VERSION "HIPBNYYYYYYYYYYYYYYYYYYYYYYYYYYYNNNYNNNNNN/4/%%%/4/'%**4NNN///"

NS_ :

BS_:

BU_: P4USimulation

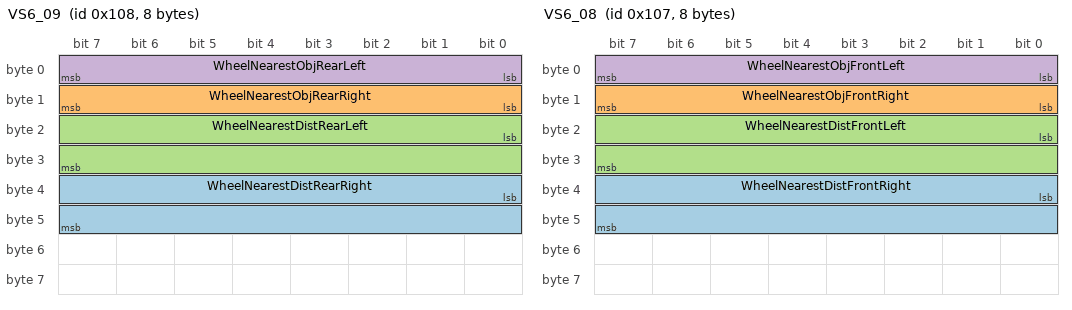
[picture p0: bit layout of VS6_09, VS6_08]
BO_ 264 VS6_09: 8 Vector__XXX
 SG_ WheelNearestDistRearRight : 32|16@1+ (1,0) [0|65535] "mm" Vector__XXX
 SG_ WheelNearestObjRearRight : 8|8@1+ (1,0) [0|255] "ID" Vector__XXX
 SG_ WheelNearestDistRearLeft : 16|16@1+ (1,0) [0|65535] "mm" Vector__XXX
 SG_ WheelNearestObjRearLeft : 0|8@1+ (1,0) [0|255] "ID" Vector__XXX

BO_ 263 VS6_08: 8 Vector__XXX
 SG_ WheelNearestDistFrontRight : 32|16@1+ (1,0) [0|65535] "mm" Vector__XXX
 SG_ WheelNearestObjFrontRight : 8|8@1+ (1,0) [0|255] "ID" Vector__XXX
 SG_ WheelNearestDistFrontLeft : 16|16@1+ (1,0) [0|65535] "mm" Vector__XXX
 SG_ WheelNearestObjFrontLeft : 0|8@1+ (1,0) [0|255] "ID" Vector__XXX

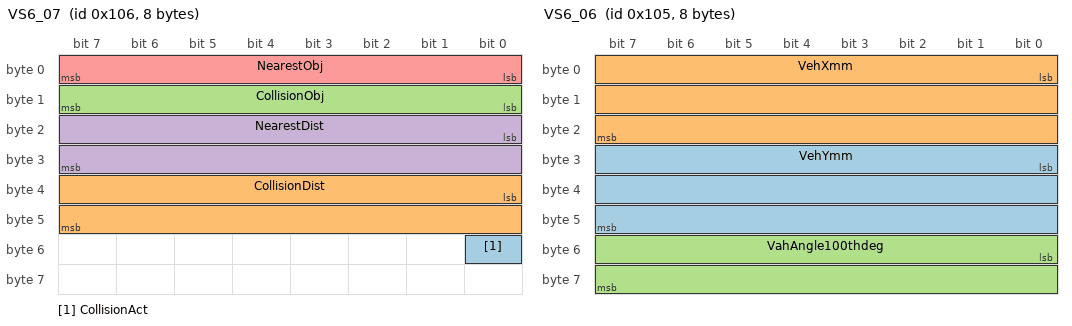
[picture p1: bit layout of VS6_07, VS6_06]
BO_ 262 VS6_07: 8 Vector__XXX
 SG_ CollisionAct : 48|1@1+ (1,0) [0|0] "" Vector__XXX
 SG_ CollisionDist : 32|16@1+ (1,0) [0|65535] "mm" Vector__XXX
 SG_ CollisionObj : 8|8@1+ (1,0) [0|255] "ID" Vector__XXX
 SG_ NearestDist : 16|16@1+ (1,0) [0|65535] "mm" Vector__XXX
 SG_ NearestObj : 0|8@1+ (1,0) [0|255] "ID" Vector__XXX

BO_ 261 VS6_06: 8 Vector__XXX
 SG_ VehYmm : 24|24@1- (1,0) [-8388608|8388607] "mm" Vector__XXX
 SG_ VehXmm : 0|24@1- (1,0) [-8388608|8388607] "mm" Vector__XXX
 SG_ VahAngle100thdeg : 48|16@1- (1,0) [0|0] "100thdeg" Vector__XXX

BO_ 260 VS6_05: 8 Vector__XXX
 SG_ WheelAngleFront : 0|16@1- (0.01,0) [-327.68|327.67] "degree" Vector__XXX
 SG_ WheelAngleRear : 16|16@1- (0.01,0) [-327.68|327.67] "degree" Vector__XXX

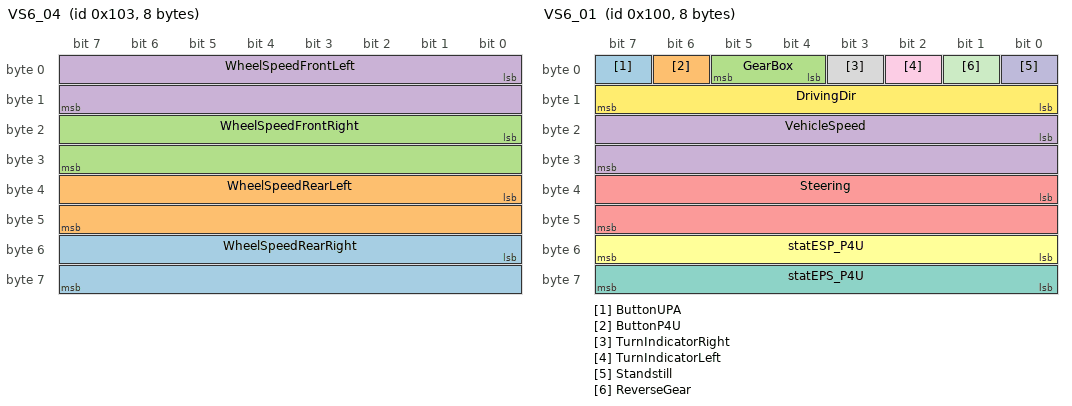
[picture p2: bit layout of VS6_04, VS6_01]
BO_ 259 VS6_04: 8 Vector__XXX
 SG_ WheelSpeedRearRight : 48|16@1- (0.01,0) [-327.68|327.67] "km/h" Vector__XXX
 SG_ WheelSpeedRearLeft : 32|16@1- (0.01,0) [-327.68|327.67] "km/h" Vector__XXX
 SG_ WheelSpeedFrontRight : 16|16@1- (0.01,0) [-327.68|327.67] "km/h" Vector__XXX
 SG_ WheelSpeedFrontLeft : 0|16@1- (0.01,0) [-327.68|327.67] "km/h" Vector__XXX

BO_ 256 VS6_01: 8 Vector__XXX
 SG_ ButtonUPA : 7|1@1+ (1,0) [0|0] "" Vector__XXX
 SG_ ButtonP4U : 6|1@1+ (1,0) [0|0] "" Vector__XXX
 SG_ GearBox : 4|2@1+ (1,0) [0|3] "" Vector__XXX
 SG_ VehicleSpeed : 16|16@1+ (0.01,0) [0|655.35] "km/h"  P4USimulation
 SG_ Steering : 32|16@1- (1,0) [-32768|32767] "see_ratio_table"  P4USimulation
 SG_ statESP_P4U : 48|8@1+ (1,0) [0|255] ""  P4USimulation
 SG_ statEPS_P4U : 56|8@1+ (1,0) [0|255] ""  P4USimulation
 SG_ TurnIndicatorRight : 3|1@1+ (1,0) [0|1] ""  P4USimulation
 SG_ TurnIndicatorLeft : 2|1@1+ (1,0) [0|1] ""  P4USimulation
 SG_ Standstill : 0|1@1+ (1,0) [0|1] ""  P4USimulation
 SG_ ReverseGear : 1|1@1+ (1,0) [0|1] ""  P4USimulation
 SG_ DrivingDir : 8|8@1- (1,0) [-128|127] ""  P4USimulation

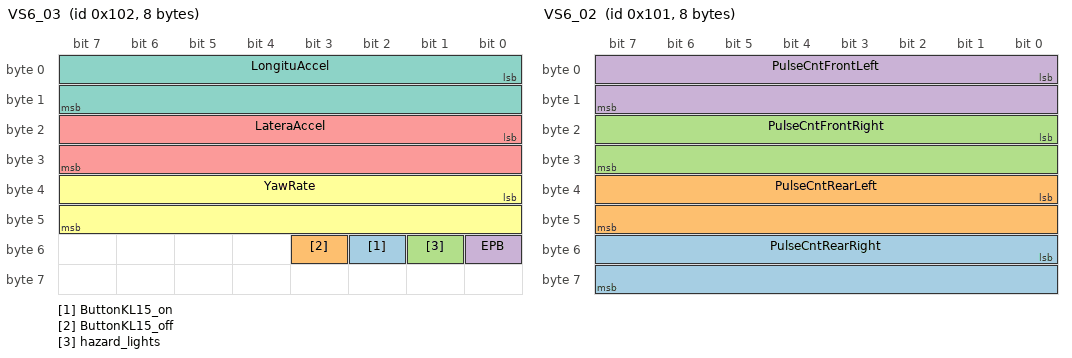
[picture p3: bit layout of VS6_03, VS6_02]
BO_ 258 VS6_03: 8 Vector__XXX
 SG_ ButtonKL15_on : 50|1@1+ (1,0) [0|0] "" Vector__XXX
 SG_ ButtonKL15_off : 51|1@1+ (1,0) [0|0] "" Vector__XXX
 SG_ hazard_lights : 49|1@1+ (1,0) [0|0] "-" Vector__XXX
 SG_ EPB : 48|1@1- (1,0) [0|0] "-" Vector__XXX
 SG_ LateraAccel : 16|16@1- (0.01,0) [0|0] "m/sec^2"  P4USimulation
 SG_ YawRate : 32|16@1- (0.01,0) [-327.68|327.67] "degree/sec"  P4USimulation
 SG_ LongituAccel : 0|16@1- (0.01,0) [0|0] "m/sec^2"  P4USimulation

BO_ 257 VS6_02: 8 Vector__XXX
 SG_ PulseCntRearRight : 48|16@1+ (1,0) [0|65535] ""  P4USimulation
 SG_ PulseCntRearLeft : 32|16@1+ (1,0) [0|65535] ""  P4USimulation
 SG_ PulseCntFrontRight : 16|16@1+ (1,0) [0|65535] ""  P4USimulation
 SG_ PulseCntFrontLeft : 0|16@1+ (1,0) [0|65535] ""  P4USimulation

EV_ EnvMultiMsg_VS6: 0 [0|0] "" 0 1 DUMMY_NODE_VECTOR0 Vector__XXX;

EV_ EnvSendVS6_Standstill: 0 [0|1] "" 0 2 DUMMY_NODE_VECTOR0 Vector__XXX;

EV_ EnvSendVS6_statESP_P4U: 0 [0|1] "" 0 3 DUMMY_NODE_VECTOR0 Vector__XXX;

EV_ EnvSendVS6_statEPS_P4U: 0 [0|1] "" 0 4 DUMMY_NODE_VECTOR0 Vector__XXX;

EV_ EnvSendVS6_LongituAccel: 0 [0|1] "" 0 5 DUMMY_NODE_VECTOR0 Vector__XXX;

EV_ EnvSendVS6_LateraAccel: 0 [0|1] "" 0 6 DUMMY_NODE_VECTOR0 Vector__XXX;

EV_ EnvSendVS6_DrivingDir: 0 [0|1] "" 0 7 DUMMY_NODE_VECTOR0 Vector__XXX;

EV_ EnvSendVS6_ReverseGear: 0 [0|1] "" 0 8 DUMMY_NODE_VECTOR0 Vector__XXX;

EV_ EnvSendVS6_SteeringWheelAngle: 0 [0|1] "" 0 9 DUMMY_NODE_VECTOR0 Vector__XXX;

EV_ EnvSendVS6_YawRate: 0 [0|1] "" 0 10 DUMMY_NODE_VECTOR0 Vector__XXX;

EV_ EnvSendVS6_VehicleSpeed: 0 [0|1] "" 0 11 DUMMY_NODE_VECTOR0 Vector__XXX;

EV_ EnvSendVS6_TurnIndicatorRight: 0 [0|1] "" 0 12 DUMMY_NODE_VECTOR0 Vector__XXX;

EV_ EnvSendVS6_TurnIndicatorLeft: 0 [0|1] "" 0 13 DUMMY_NODE_VECTOR0 Vector__XXX;

EV_ EnvSendVS6_PulseCntFrontRight: 0 [0|1] "" 0 14 DUMMY_NODE_VECTOR0 Vector__XXX;

EV_ EnvSendVS6_PulseCntFrontLeft: 0 [0|1] "" 0 15 DUMMY_NODE_VECTOR0 Vector__XXX;

EV_ EnvSendVS6_PulseCntRearLeft: 0 [0|1] "" 0 16 DUMMY_NODE_VECTOR0 Vector__XXX;

EV_ EnvSendVS6_PulseCntRearRight: 0 [0|1] "" 0 17 DUMMY_NODE_VECTOR0 Vector__XXX;

CM_ "CAN communication matrix for body electronics
*******************************************************

implemented: turn lights, warning lights, windows


";
CM_ SG_ 264 WheelNearestDistRearRight "Direct distance from wheel to nearest object in mm";
CM_ SG_ 264 WheelNearestObjRearRight "Id of nearest object from wheel";
CM_ SG_ 264 WheelNearestDistRearLeft "Direct distance from wheel to nearest object in mm";
CM_ SG_ 264 WheelNearestObjRearLeft "Id of nearest object from wheel";
CM_ SG_ 263 WheelNearestDistFrontRight "Direct distance from wheel to nearest object in mm";
CM_ SG_ 263 WheelNearestObjFrontRight "Id of nearest object from wheel";
CM_ SG_ 263 WheelNearestDistFrontLeft "Direct distance from wheel to nearest object in mm";
CM_ SG_ 263 WheelNearestObjFrontLeft "Id of nearest object from wheel";
CM_ SG_ 262 CollisionAct "Collision active with an obstacle";
CM_ SG_ 262 CollisionDist "Distance to nearest object in driving tube in mm (0=collision active)";
CM_ SG_ 262 CollisionObj "Id of nearest object in driving tube";
CM_ SG_ 262 NearestDist "Direct distance from vehicle to nearest object in mm";
CM_ SG_ 262 NearestObj "Id of nearest object to vehicle";
CM_ SG_ 260 WheelAngleFront "Wheel Angle of front axis.";
CM_ SG_ 260 WheelAngleRear "Wheel Angle of rear axis for simulation of a vehicle with steerable rear axis.";
CM_ SG_ 256 VehicleSpeed "Vehicle speed";
CM_ SG_ 256 Steering "Steering angle";
CM_ SG_ 256 statESP_P4U "Status ESP to Park4U";
CM_ SG_ 256 statEPS_P4U "Status EPS to Park4U";
CM_ SG_ 256 TurnIndicatorRight "Turn indicator right";
CM_ SG_ 256 TurnIndicatorLeft "Turn indicator left";
CM_ SG_ 256 Standstill "Standstill";
CM_ SG_ 256 ReverseGear "Reverse gear";
CM_ SG_ 256 DrivingDir "Driving direction";
CM_ SG_ 258 LateraAccel "Lateral acceleration sensor";
CM_ SG_ 258 YawRate "Yaw rate sensor";
CM_ SG_ 258 LongituAccel "Longitudinal acceleration sensor";
CM_ SG_ 257 PulseCntRearRight "Pulse counter rear right";
CM_ SG_ 257 PulseCntRearLeft "Pulse counter rear left";
CM_ SG_ 257 PulseCntFrontRight "Pulse counter front right";
CM_ SG_ 257 PulseCntFrontLeft "Pulse counter front left";
CM_ EV_ EnvMultiMsg_VS6 "Schalter zum Zu/Abschalten der von VS6 gesendeten Botschaften";
CM_ EV_ EnvSendVS6_Standstill "Sendeflag für VS6-Signal XXX";
CM_ EV_ EnvSendVS6_statESP_P4U "Sendeflag für VS6-Signal XXX";
CM_ EV_ EnvSendVS6_statEPS_P4U "Sendeflag für VS6-Signal XXX";
CM_ EV_ EnvSendVS6_LongituAccel "Sendeflag für VS6-Signal XXX";
CM_ EV_ EnvSendVS6_LateraAccel "Sendeflag für VS6-Signal XXX";
CM_ EV_ EnvSendVS6_DrivingDir "Sendeflag für VS6-Signal XXX";
CM_ EV_ EnvSendVS6_ReverseGear "Sendeflag für VS6-Signal XXX";
CM_ EV_ EnvSendVS6_SteeringWheelAngle "Sendeflag für VS6-Signal XXX";
CM_ EV_ EnvSendVS6_YawRate "Sendeflag für VS6-Signal XXX";
CM_ EV_ EnvSendVS6_VehicleSpeed "Sendeflag für VS6-Signal XXX";
CM_ EV_ EnvSendVS6_TurnIndicatorRight "Sendeflag für VS6-Signal XXX";
CM_ EV_ EnvSendVS6_TurnIndicatorLeft "Sendeflag für VS6-Signal XXX";
CM_ EV_ EnvSendVS6_PulseCntFrontRight "Sendeflag für VS6-Signal XXX";
CM_ EV_ EnvSendVS6_PulseCntFrontLeft "Sendeflag für VS6-Signal XXX";
CM_ EV_ EnvSendVS6_PulseCntRearLeft "Sendeflag für VS6-Signal XXX";
CM_ EV_ EnvSendVS6_PulseCntRearRight "Sendeflag für VS6-Signal XXX";
BA_DEF_ BO_  "DiagRequest" ENUM  "no","yes";
BA_DEF_ BU_  "TpTxIdentifier" HEX 0 536870911;
BA_DEF_ BU_  "TpRxIdentifier" HEX 0 536870911;
BA_DEF_ BU_  "TpCanBus" INT 1 2;
BA_DEF_ BU_  "TpUseFC" INT 0 1;
BA_DEF_DEF_  "DiagRequest" "no";
BA_DEF_DEF_  "TpTxIdentifier" 1;
BA_DEF_DEF_  "TpRxIdentifier" 1;
BA_DEF_DEF_  "TpCanBus" 1;
BA_DEF_DEF_  "TpUseFC" 1;
BA_ "DiagRequest" BO_ 257 1;
VAL_ 256 GearBox 3 "D" 2 "N" 1 "R" 0 "P" ;
VAL_ 256 DrivingDir 2 "backwards" 1 "foreward" 0 "unknown" ;
